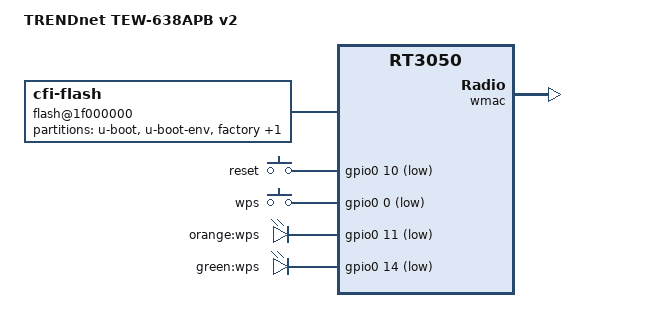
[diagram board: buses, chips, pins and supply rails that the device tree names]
#include "rt3050.dtsi"

#include <dt-bindings/gpio/gpio.h>
#include <dt-bindings/input/input.h>

/ {
	compatible = "trendnet,tew-638apb-v2", "ralink,rt3050-soc";
	model = "TRENDnet TEW-638APB v2";

	aliases {
		led-boot = &led_wps_green;
		led-failsafe = &led_wps_green;
		led-running = &led_wps_green;
		led-upgrade = &led_wps_green;
	};

	flash@1f000000 {
		compatible = "cfi-flash";
		reg = <0x1f000000 0x400000>;
		bank-width = <2>;
		device-width = <2>;

		partitions {
			compatible = "fixed-partitions";
			#address-cells = <1>;
			#size-cells = <1>;

			partition@0 {
				label = "u-boot";
				reg = <0x0 0x30000>;
				read-only;
			};

			partition@30000 {
				label = "u-boot-env";
				reg = <0x30000 0x10000>;
				read-only;
			};

			factory: partition@40000 {
				label = "factory";
				reg = <0x40000 0x10000>;
				read-only;
			};

			partition@50000 {
				compatible = "denx,uimage";
				label = "firmware";
				reg = <0x50000 0x3b0000>;
			};
		};
	};

	keys {
		compatible = "gpio-keys-polled";
		poll-interval = <20>;

		reset {
			label = "reset";
			gpios = <&gpio0 10 GPIO_ACTIVE_LOW>;
			linux,code = <KEY_RESTART>;
		};

		wps {
			label = "wps";
			gpios = <&gpio0 0 GPIO_ACTIVE_LOW>;
			linux,code = <KEY_WPS_BUTTON>;
		};
	};

	leds {
		compatible = "gpio-leds";

		wps {
			label = "orange:wps";
			gpios = <&gpio0 11 GPIO_ACTIVE_LOW>;
		};

		led_wps_green: wps2 {
			label = "green:wps";
			gpios = <&gpio0 14 GPIO_ACTIVE_LOW>;
		};
	};
};

&state_default {
	gpio {
		groups = "uartf";
		function = "gpio";
	};
};

&ethernet {
	mtd-mac-address = <&factory 0x4>;
};

&esw {
	mediatek,portmap = <0x2f>;
};

&wmac {
	ralink,mtd-eeprom = <&factory 0x0>;
};
